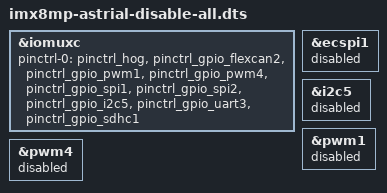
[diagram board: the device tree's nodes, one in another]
// SPDX-License-Identifier: (GPL-2.0+ OR MIT)
/*
 * Copyright 2019 NXP
 * Copyright 2024 Koan Software
 */

/dts-v1/;

#include "imx8mp-astrial-base.dtsi"

&iomuxc {
	pinctrl-0 = <
		&pinctrl_hog
		&pinctrl_gpio_flexcan2
		&pinctrl_gpio_pwm1
		&pinctrl_gpio_pwm4
		&pinctrl_gpio_spi1
		&pinctrl_gpio_spi2
		&pinctrl_gpio_i2c5
		&pinctrl_gpio_uart3
		&pinctrl_gpio_sdhc1
	>;
};

&ecspi1 {
	status = "disabled";
};

&i2c5 {
	status = "disabled";
};

&pwm1 {
	status = "disabled";
};

&pwm4 {
	status = "disabled";
};
